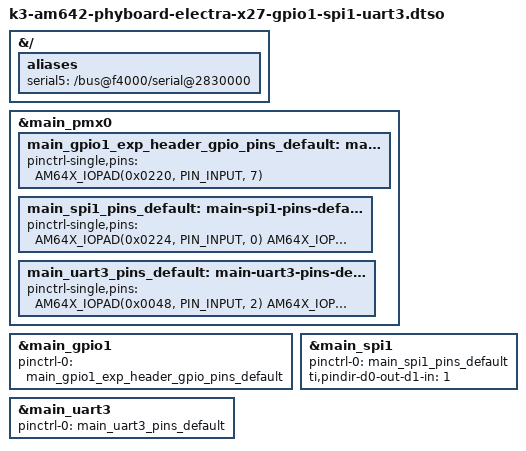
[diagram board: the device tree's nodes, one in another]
// SPDX-License-Identifier: GPL-2.0-only OR MIT
/*
 * Copyright (C) 2025 PHYTEC Messtechnik GmbH
 * Authors:
 *   Wadim Egorov <w.egorov@phytec.de>
 *   Daniel Schultz <d.schultz@phytec.de>
 *
 * GPIO, SPI and UART examples for the X27 expansion connector.
 */

/dts-v1/;
/plugin/;

#include "k3-pinctrl.h"

&{/} {
	aliases {
		serial5 = "/bus@f4000/serial@2830000";
	};
};

&main_pmx0 {
	main_gpio1_exp_header_gpio_pins_default: main-gpio1-exp-header-gpio-pins-default {
		pinctrl-single,pins = <
			AM64X_IOPAD(0x0220, PIN_INPUT, 7)	/* (D14) SPI1_CS1.GPIO1_48 */
		>;
	};

	main_spi1_pins_default: main-spi1-pins-default {
		pinctrl-single,pins = <
			AM64X_IOPAD(0x0224, PIN_INPUT, 0)	/* (C14) SPI1_CLK */
			AM64X_IOPAD(0x021C, PIN_OUTPUT, 0)	/* (B14) SPI1_CS0 */
			AM64X_IOPAD(0x0228, PIN_OUTPUT, 0)	/* (B15) SPI1_D0 */
			AM64X_IOPAD(0x022C, PIN_INPUT, 0)	/* (A15) SPI1_D1 */
		>;
	};

	main_uart3_pins_default: main-uart3-pins-default {
		pinctrl-single,pins = <
			AM64X_IOPAD(0x0048, PIN_INPUT, 2)       /* (U20) GPMC0_AD3.UART3_RXD */
			AM64X_IOPAD(0x004c, PIN_OUTPUT, 2)      /* (U18) GPMC0_AD4.UART3_TXD */
		>;
	};
};

&main_gpio1 {
	pinctrl-names = "default";
	pinctrl-0 = <&main_gpio1_exp_header_gpio_pins_default>;
	status = "okay";
};

&main_spi1 {
	pinctrl-names = "default";
	pinctrl-0 = <&main_spi1_pins_default>;
	ti,pindir-d0-out-d1-in = <1>;
	status = "okay";
};

&main_uart3 {
	pinctrl-names = "default";
	pinctrl-0 = <&main_uart3_pins_default>;
	status = "okay";
};
